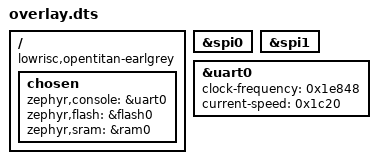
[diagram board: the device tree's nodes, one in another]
/ {
	compatible = "lowrisc,opentitan-earlgrey";
	chosen {
		zephyr,console = &uart0;
		zephyr,flash = &flash0;
		zephyr,sram = &ram0;
	};
};
&spi0{
	status = "okay";
};
&spi1{
	status = "okay";
};
&uart0{
	status = "okay";
	clock-frequency = < 0x1e848 >;
	current-speed = < 0x1c20 >;
};
